AUTOSAR XML (schema 00046)
package /ComponentTypes
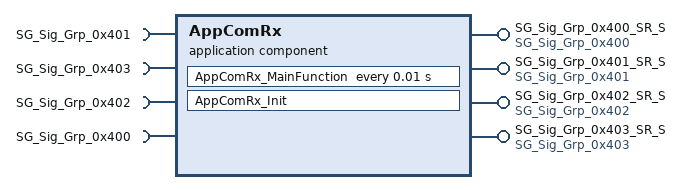
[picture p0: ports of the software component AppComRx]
  application sw component type AppComRx
    4 x require port:
      SG_Sig_Grp_0x401: nonqueued-receiver-com-spec{data-element=SG_Sig_Grp_0x401, init-value=fields=[Button1_Control:0, Button2_Control:0, Button3_Control:0, Button4_Control:0]}, required-interface=SG_Sig_Grp_0x401
      SG_Sig_Grp_0x403: nonqueued-receiver-com-spec{data-element=SG_Sig_Grp_0x403, init-value=fields=[Sig_0x403_Used_1:0, Sig_0x403_Used_2:0, Sig_0x403_Used_3:0, Sig_0x403_Used_4:0, Sig_0x403_Used_5:0]}, required-interface=SG_Sig_Grp_0x403
      SG_Sig_Grp_0x402: nonqueued-receiver-com-spec{data-element=SG_Sig_Grp_0x402, init-value=fields=[Sig_0x402_Used_1:0, Sig_0x402_Used_2:0, Sig_0x402_Used_3:0, Sig_0x402_Used_4:0, Sig_0x402_Used_5:0]}, required-interface=SG_Sig_Grp_0x402
      SG_Sig_Grp_0x400: nonqueued-receiver-com-spec{data-element=SG_Sig_Grp_0x400, end-to-end-transformation-com-spec-props=disable-end-to-end-check=false, uses-end-to-end-protection=true, enable-update=true, init-value=fields=[CrcSig_Pack_0:0, CrcSig_Pack_1:0, CrcSig_Pack_2:0, Led1_Control:1, Led2_Control:1, Led3_Control:1, Led4_Control:1, SupB_Checksum_0x400:0, SupB_Counter_0x400:0]}, required-interface=SG_Sig_Grp_0x400
    4 x provide port:
      SG_Sig_Grp_0x400_SR_S: nonqueued-sender-com-spec{data-element=SG_Sig_Grp_0x400, init-value=fields=[CrcSig_Pack_0:0, CrcSig_Pack_1:0, CrcSig_Pack_2:0, Led1_Control:1, Led2_Control:1, Led3_Control:1, Led4_Control:1, SupB_Checksum_0x400:0, SupB_Counter_0x400:0]}, provided-interface=SG_Sig_Grp_0x400
      SG_Sig_Grp_0x401_SR_S: nonqueued-sender-com-spec{data-element=SG_Sig_Grp_0x401, init-value=fields=[Button1_Control:0, Button2_Control:0, Button3_Control:0, Button4_Control:0]}, provided-interface=SG_Sig_Grp_0x401
      SG_Sig_Grp_0x402_SR_S: nonqueued-sender-com-spec{data-element=SG_Sig_Grp_0x402, init-value=fields=[Sig_0x402_Used_1:0, Sig_0x402_Used_2:0, Sig_0x402_Used_3:0, Sig_0x402_Used_4:0, Sig_0x402_Used_5:0]}, provided-interface=SG_Sig_Grp_0x402
      SG_Sig_Grp_0x403_SR_S: nonqueued-sender-com-spec{data-element=SG_Sig_Grp_0x403, init-value=fields=[Sig_0x403_Used_1:0, Sig_0x403_Used_2:0, Sig_0x403_Used_3:0, Sig_0x403_Used_4:0, Sig_0x403_Used_5:0]}, provided-interface=SG_Sig_Grp_0x403
    behavior AppComRx_InternalBehavior
      init event AppComRx_InitEvent: start-on-event=AppComRx_Init
      timing event TMT_AppComRx_MainFunction: start-on-event=AppComRx_MainFunction, period=0.01
      runnable AppComRx_MainFunction
        data-receive-point-by-arguments:
          4 x access:
            REC_SG_Sig_Grp_0x{400..403}_SG_Sig_Grp_0x{400..403}: accessed-variable=SG_Sig_Grp_0x{400..403}.SG_Sig_Grp_0x{400..403}
        data-send-points:
          4 x access:
            SEND_SG_Sig_Grp_0x{400..403}_SR_S_SG_Sig_Grp_0x{400..403}: accessed-variable=SG_Sig_Grp_0x{400..403}_SR_S.SG_Sig_Grp_0x{400..403}
      runnable AppComRx_Init
  swc implementation AppComRx_Implementation: behavior=AppComRx_InternalBehavior
